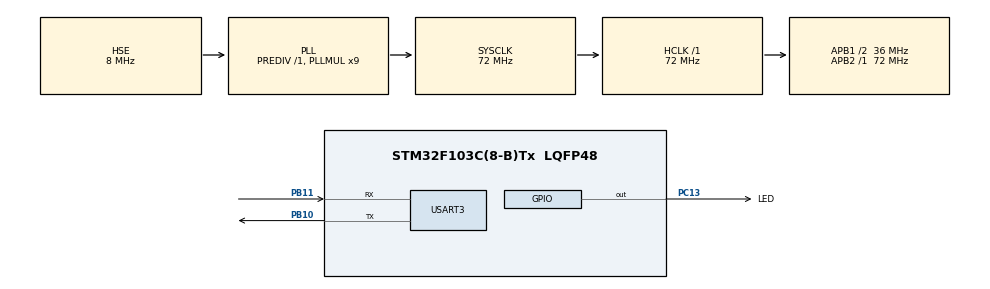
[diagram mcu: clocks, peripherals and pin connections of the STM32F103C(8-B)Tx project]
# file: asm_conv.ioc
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Mcu.Family=STM32F1
Mcu.Name=STM32F103C(8-B)Tx
Mcu.Package=LQFP48
NVIC.PriorityGroup=NVIC_PRIORITYGROUP_4
NVIC.USART3_IRQn=true\:0\:0\:false\:false\:true\:true\:true\:true
PA13.Mode=Serial_Wire
PA13.Signal=SYS_JTMS-SWDIO
PA14.Mode=Serial_Wire
PA14.Signal=SYS_JTCK-SWCLK
PB10.Mode=Asynchronous
PB10.Signal=USART3_TX
PB11.Mode=Asynchronous
PB11.Signal=USART3_RX
PC13-TAMPER-RTC.GPIO_Label=LED
PC13-TAMPER-RTC.Signal=GPIO_Output
PD0-OSC_IN.Mode=HSE-External-Oscillator
PD0-OSC_IN.Signal=RCC_OSC_IN
PD1-OSC_OUT.Mode=HSE-External-Oscillator
PD1-OSC_OUT.Signal=RCC_OSC_OUT
ProjectManager.HeapSize=0x200
ProjectManager.StackSize=0x400
ProjectManager.TargetToolchain=STM32CubeIDE
RCC.AHBFreq_Value=72000000
RCC.APB1CLKDivider=RCC_HCLK_DIV2
RCC.APB1Freq_Value=36000000
RCC.APB1TimFreq_Value=72000000
RCC.APB2Freq_Value=72000000
RCC.APB2TimFreq_Value=72000000
RCC.HCLKFreq_Value=72000000
RCC.PLLMUL=RCC_PLL_MUL9
RCC.PLLSourceVirtual=RCC_PLLSOURCE_HSE
RCC.SYSCLKFreq_VALUE=72000000
RCC.SYSCLKSource=RCC_SYSCLKSOURCE_PLLCLK
RCC.USBFreq_Value=72000000
USART3.VirtualMode=VM_ASYNC
board=custom

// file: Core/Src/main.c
/* USER CODE BEGIN Header */
/**
 ******************************************************************************
 * @file           : main.c
 * @brief          : Main program body
 ******************************************************************************
 * @attention
 *
 * <h2><center>&copy; Copyright (c) 2021 STMicroelectronics.
 * All rights reserved.</center></h2>
 *
 * This software component is licensed by ST under BSD 3-Clause license,
 * the "License"; You may not use this file except in compliance with the
 * License. You may obtain a copy of the License at:
 *                        opensource.org/licenses/BSD-3-Clause
 *
 ******************************************************************************
 */
/* USER CODE END Header */
#include "main.h"

/* USER CODE BEGIN Includes */
#include "samples.h"
#include "dwt.h"
#include <stdio.h>
/* USER CODE END Includes */

UART_HandleTypeDef huart3;

/* USER CODE BEGIN PV */
static int y[N_SAMPLES_Y];
static int y_c[N_SAMPLES_Y];
/* USER CODE END PV */

void SystemClock_Config(void);
static void MX_GPIO_Init(void);
static void MX_USART3_UART_Init(void);

/* USER CODE BEGIN 0 */

void conv_c(convData_t * datos)
{
	int i, j;
	long long acum;

	for (i = 0; i < (datos->nx + datos->nh); i++) {
		datos->y[i] = 0;
	}

	for (i = 0; i < datos->nx; i++) {
		acum = 0;
		for (j = 0; j < datos->nh; j++) {
			acum = (long long)datos->y[i+j] << 32;
			acum += (long long)datos->h[j] * (long long)datos->x[i];
			datos->y[i+j] = acum >> 32;
		}
	}
}

/* USER CODE END 0 */

int main(void)
{
	/* USER CODE BEGIN 1 */
	convData_t datos;

	/* USER CODE END 1 */

	/* MCU Configuration--------------------------------------------------------*/

	/* Reset of all peripherals, Initializes the Flash interface and the Systick. */
	HAL_Init();

	/* Configure the system clock */
	SystemClock_Config();

	/* Initialize all configured peripherals */
	MX_GPIO_Init();
	MX_USART3_UART_Init();
	/* USER CODE BEGIN 2 */
	dwt_init();

	//--------------------------------

	datos.x = x_3k;
	datos.nx = N_SAMPLES_X;
	datos.h = h;
	datos.nh = N_TAPS;

	datos.y = y_c;
	dwt_reset();
	conv_c(&datos);
	printf("conv_c 3k: %lu ciclos\r\n", dwt_read());

	datos.y = y;
	dwt_reset();
	conv_asm(&datos);
	printf("conv_asm 3k: %lu ciclos\r\n", dwt_read());
	for (int i = 0; i < N_SAMPLES_Y; i++) {
		if (y[i] != y_c[i]) {
			Error_Handler();
		}
		else {
			printf("%d,\r\n", y[i]);
		}
	}

	//--------------------------------

	datos.x = x_1k;
	datos.y = y_c;
	dwt_reset();
	conv_c(&datos);
	printf("conv_c 1k: %lu ciclos\r\n", dwt_read());

	datos.y = y;
	dwt_reset();
	conv_asm(&datos);
	printf("conv_asm 1k: %lu ciclos\r\n", dwt_read());
	for (int i = 0; i < N_SAMPLES_Y; i++) {
		if (y[i] != y_c[i]) {
			Error_Handler();
		}
		else {
			printf("%d,\r\n", y[i]);
		}
	}

	/* USER CODE END 2 */

	/* Infinite loop */
	while (1)
	{

	}
}

void SystemClock_Config(void)
{
	RCC_OscInitTypeDef RCC_OscInitStruct = {0};
	RCC_ClkInitTypeDef RCC_ClkInitStruct = {0};

	/** Initializes the RCC Oscillators according to the specified parameters
	 * in the RCC_OscInitTypeDef structure.
	 */
	RCC_OscInitStruct.OscillatorType = RCC_OSCILLATORTYPE_HSE;
	RCC_OscInitStruct.HSEState = RCC_HSE_ON;
	RCC_OscInitStruct.HSEPredivValue = RCC_HSE_PREDIV_DIV1;
	RCC_OscInitStruct.HSIState = RCC_HSI_ON;
	RCC_OscInitStruct.PLL.PLLState = RCC_PLL_ON;
	RCC_OscInitStruct.PLL.PLLSource = RCC_PLLSOURCE_HSE;
	RCC_OscInitStruct.PLL.PLLMUL = RCC_PLL_MUL9;
	if (HAL_RCC_OscConfig(&RCC_OscInitStruct) != HAL_OK)
	{
		Error_Handler();
	}

	/** Initializes the CPU, AHB and APB buses clocks
	 */
	RCC_ClkInitStruct.ClockType = RCC_CLOCKTYPE_HCLK|RCC_CLOCKTYPE_SYSCLK
			|RCC_CLOCKTYPE_PCLK1|RCC_CLOCKTYPE_PCLK2;
	RCC_ClkInitStruct.SYSCLKSource = RCC_SYSCLKSOURCE_PLLCLK;
	RCC_ClkInitStruct.AHBCLKDivider = RCC_SYSCLK_DIV1;
	RCC_ClkInitStruct.APB1CLKDivider = RCC_HCLK_DIV2;
	RCC_ClkInitStruct.APB2CLKDivider = RCC_HCLK_DIV1;

	if (HAL_RCC_ClockConfig(&RCC_ClkInitStruct, FLASH_LATENCY_2) != HAL_OK)
	{
		Error_Handler();
	}
}

static void MX_USART3_UART_Init(void)
{

	huart3.Instance = USART3;
	huart3.Init.BaudRate = 115200;
	huart3.Init.WordLength = UART_WORDLENGTH_8B;
	huart3.Init.StopBits = UART_STOPBITS_1;
	huart3.Init.Parity = UART_PARITY_NONE;
	huart3.Init.Mode = UART_MODE_TX_RX;
	huart3.Init.HwFlowCtl = UART_HWCONTROL_NONE;
	huart3.Init.OverSampling = UART_OVERSAMPLING_16;
	if (HAL_UART_Init(&huart3) != HAL_OK)
	{
		Error_Handler();
	}

}

static void MX_GPIO_Init(void)
{
	GPIO_InitTypeDef GPIO_InitStruct = {0};

	/* GPIO Ports Clock Enable */
	__HAL_RCC_GPIOC_CLK_ENABLE();
	__HAL_RCC_GPIOD_CLK_ENABLE();
	__HAL_RCC_GPIOB_CLK_ENABLE();
	__HAL_RCC_GPIOA_CLK_ENABLE();

	/*Configure GPIO pin Output Level */
	HAL_GPIO_WritePin(LED_GPIO_Port, LED_Pin, GPIO_PIN_RESET);

	/*Configure GPIO pin : LED_Pin */
	GPIO_InitStruct.Pin = LED_Pin;
	GPIO_InitStruct.Mode = GPIO_MODE_OUTPUT_PP;
	GPIO_InitStruct.Pull = GPIO_NOPULL;
	GPIO_InitStruct.Speed = GPIO_SPEED_FREQ_LOW;
	HAL_GPIO_Init(LED_GPIO_Port, &GPIO_InitStruct);

}

/* USER CODE BEGIN 4 */

/** @brief Retarget printf() to UART3 */
int __io_putchar(int ch)
{
	HAL_UART_Transmit(&huart3, (uint8_t *)&ch, 1, 10);
	return ch;
}

/* USER CODE END 4 */

void Error_Handler(void)
{
	__disable_irq();
	while (1)
	{
	}
}
